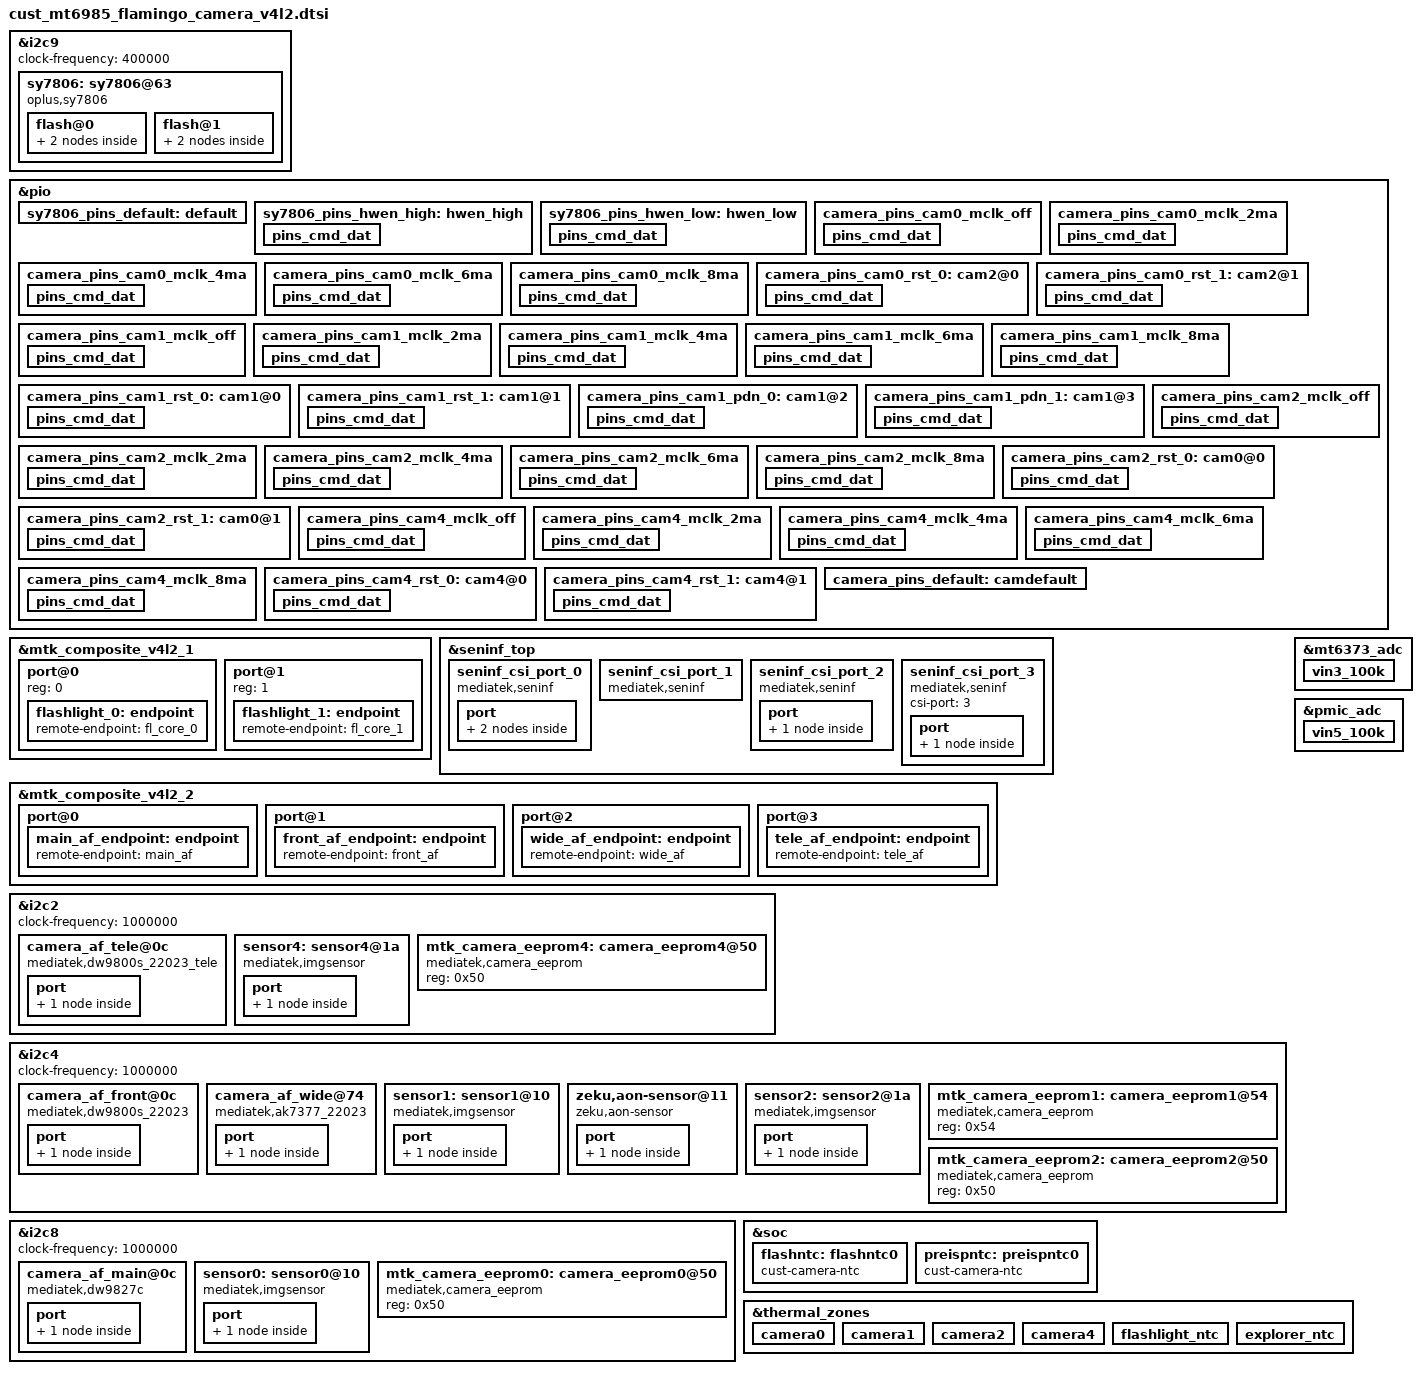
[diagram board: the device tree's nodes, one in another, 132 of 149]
// SPDX-License-Identifier: GPL-2.0
/* Copyright (c) 2020 MediaTek Inc. */

#include <dt-bindings/clock/mt6985-clk.h>
#include "mediatek/flamingo-regulator.dtsi"
&i2c9 {
	clock-frequency = <400000>;
	#address-cells = <1>;
	#size-cells = <0>;
	sy7806:sy7806@63 {
		compatible = "oplus,sy7806";
		#address-cells = <1>;
		#size-cells = <0>;
		reg = <0x63>;
		#cooling-cells = <2>;
		pinctrl-names = "default", "hwen_high", "hwen_low";
		pinctrl-0 = <&sy7806_pins_default>;
		pinctrl-1 = <&sy7806_pins_hwen_high>;
		pinctrl-2 = <&sy7806_pins_hwen_low>;
		status = "okay";
		flash@0{
			reg = <0>;
			type = <0>;
			ct = <0>;
			part = <0>;
			port {
				fl_core_0: endpoint {
					remote-endpoint = <&flashlight_0>;
				};
			};
		};
		flash@1{
			reg = <1>;
			type = <0>;
			ct = <1>;
			part = <0>;
			port {
				fl_core_1: endpoint {
					remote-endpoint = <&flashlight_1>;
				};
			};
		};
	};
};

&pio {
	sy7806_pins_default: default {
	};

	sy7806_pins_hwen_high: hwen_high {
		pins_cmd_dat {
			pinmux = <PINMUX_GPIO33__FUNC_GPIO33>;
			slew-rate = <1>;
			output-high;
		};
	};

	sy7806_pins_hwen_low: hwen_low {
		pins_cmd_dat {
			pinmux = <PINMUX_GPIO33__FUNC_GPIO33>;
			slew-rate = <1>;
			output-low;
		};
	};
};

&mtk_composite_v4l2_1 {
	#address-cells = <1>;
	#size-cells = <0>;
	port@0 {
		reg = <0>;
		flashlight_0: endpoint {
			remote-endpoint = <&fl_core_0>;
		};
	};
	port@1 {
		reg = <1>;
		flashlight_1: endpoint {
			remote-endpoint = <&fl_core_1>;
		};
	};
};

&seninf_top {
		seninf_csi_port_0: seninf_csi_port_0 {
			compatible = "mediatek,seninf";
			csi-port = "0";
			dphy_settle_delay_dt = <17>;
#if 0
			nvmem-cells = <&csi_efuse0>;
			nvmem-cell-names = "rg_csi";
#endif
			port {
				seninf_csi_port_0_in: endpoint@0 {
					remote-endpoint = <&sensor1_out>;
				};
				seninf_csi_port_0_in2: endpoint@1 {
					remote-endpoint = <&sensor2_out>;
				};
			};
		};

		seninf_csi_port_1: seninf_csi_port_1 {
			compatible = "mediatek,seninf";
			csi-port = "1";
			hs_trail_parameter = <0x20>;
#if 0
			nvmem-cells = <&csi_efuse1>;
			nvmem-cell-names = "rg_csi";
#endif
			//port {
			// 	seninf_csi_port_1_in: endpoint {
			// 		remote-endpoint = <&sensor4_out>;
			// 	};
			// };
		};

		seninf_csi_port_2: seninf_csi_port_2 {
			compatible = "mediatek,seninf";
			csi-port = "2";
			hs_trail_parameter = <0x20>;
#if 0
			nvmem-cells = <&csi_efuse2>;
			nvmem-cell-names = "rg_csi";
#endif
			port {
				seninf_csi_port_2_in: endpoint {
					remote-endpoint = <&sensor0_out>;
				};
			};
		};

		seninf_csi_port_3: seninf_csi_port_3 {
			compatible = "mediatek,seninf";
			csi-port = "3";
#if 0
			nvmem-cells = <&csi_efuse2>;
			nvmem-cell-names = "rg_csi";
#endif
			port {
				seninf_csi_port_3_in: endpoint {
					remote-endpoint = <&sensor4_out>;
				};
			};
		};
};

/* CAMERA GPIO standardization */
&pio {
	/* REAR0 IMX890: MCLK-GPIO208, RESET-GPIO202 */
	camera_pins_cam0_mclk_off: camera_pins_cam0_mclk_off {
		pins_cmd_dat {
			pinmux = <PINMUX_GPIO208__FUNC_GPIO208>;
			drive-strength = <1>;
		};
	};
	camera_pins_cam0_mclk_2ma: camera_pins_cam0_mclk_2ma {
		pins_cmd_dat {
			pinmux = <PINMUX_GPIO208__FUNC_CMMCLK3>;
			drive-strength = <0>;
		};
	};
	camera_pins_cam0_mclk_4ma: camera_pins_cam0_mclk_4ma {
		pins_cmd_dat {
			pinmux = <PINMUX_GPIO208__FUNC_CMMCLK3>;
			drive-strength = <1>;
		};
	};
	camera_pins_cam0_mclk_6ma: camera_pins_cam0_mclk_6ma {
		pins_cmd_dat {
			pinmux = <PINMUX_GPIO208__FUNC_CMMCLK3>;
			drive-strength = <2>;
		};
	};
	camera_pins_cam0_mclk_8ma: camera_pins_cam0_mclk_8ma {
		pins_cmd_dat {
			pinmux = <PINMUX_GPIO208__FUNC_CMMCLK3>;
			drive-strength = <3>;
		};
	};
	camera_pins_cam0_rst_0: cam2@0 {
		pins_cmd_dat {
			pinmux = <PINMUX_GPIO202__FUNC_GPIO202>;
			slew-rate = <1>;
			output-low;
		};
	};
	camera_pins_cam0_rst_1: cam2@1 {
		pins_cmd_dat {
			pinmux = <PINMUX_GPIO202__FUNC_GPIO202>;
			slew-rate = <1>;
			output-high;
		};
	};
/*	camera_pins_cam0_avdd1_0: cam2@2 {
		pins_cmd_dat {
			pinmux = <PINMUX_GPIO15__FUNC_GPIO15>;
			slew-rate = <1>;
			output-low;
		};
	};
	camera_pins_cam0_avdd1_1: cam2@3 {
		pins_cmd_dat {
			pinmux = <PINMUX_GPIO15__FUNC_GPIO15>;
			slew-rate = <1>;
			output-high;
		};
	};*/
	/* FRONT IMX709: MCLK-GPIO196, RESET-GPIO148 */
	camera_pins_cam1_mclk_off: camera_pins_cam1_mclk_off {
		pins_cmd_dat {
			pinmux = <PINMUX_GPIO196__FUNC_GPIO196>;
			drive-strength = <1>;
		};
	};
	camera_pins_cam1_mclk_2ma: camera_pins_cam1_mclk_2ma {
		pins_cmd_dat {
			pinmux = <PINMUX_GPIO196__FUNC_CMMCLK0>;
			drive-strength = <0>;
		};
	};
	camera_pins_cam1_mclk_4ma: camera_pins_cam1_mclk_4ma {
		pins_cmd_dat {
			pinmux = <PINMUX_GPIO196__FUNC_CMMCLK0>;
			drive-strength = <1>;
		};
	};
	camera_pins_cam1_mclk_6ma: camera_pins_cam1_mclk_6ma {
		pins_cmd_dat {
			pinmux = <PINMUX_GPIO196__FUNC_CMMCLK0>;
			drive-strength = <2>;
		};
	};
	camera_pins_cam1_mclk_8ma: camera_pins_cam1_mclk_8ma {
		pins_cmd_dat {
			pinmux = <PINMUX_GPIO196__FUNC_CMMCLK0>;
			drive-strength = <3>;
		};
	};
	camera_pins_cam1_rst_0: cam1@0 {
		pins_cmd_dat {
			pinmux = <PINMUX_GPIO148__FUNC_GPIO148>;
			slew-rate = <1>;
			output-low;
		};
	};
	camera_pins_cam1_rst_1: cam1@1 {
		pins_cmd_dat {
			pinmux = <PINMUX_GPIO148__FUNC_GPIO148>;
			slew-rate = <1>;
			output-high;
		};
	};
	camera_pins_cam1_pdn_0: cam1@2 {
		pins_cmd_dat {
			pinmux = <PINMUX_GPIO149__FUNC_GPIO149>;
			slew-rate = <1>;
			output-low;
		};
	};
	camera_pins_cam1_pdn_1: cam1@3 {
		pins_cmd_dat {
			pinmux = <PINMUX_GPIO149__FUNC_GPIO149>;
			slew-rate = <1>;
			output-high;
		};
	};
	/* REAR1 IMX581: MCLK-GPIO198, RESET-GPIO201 */
	camera_pins_cam2_mclk_off: camera_pins_cam2_mclk_off {
		pins_cmd_dat {
			pinmux = <PINMUX_GPIO198__FUNC_GPIO198>;
			drive-strength = <1>;
		};
	};
	camera_pins_cam2_mclk_2ma: camera_pins_cam2_mclk_2ma {
		pins_cmd_dat {
			pinmux = <PINMUX_GPIO198__FUNC_CMMCLK2>;
			drive-strength = <0>;
		};
	};
	camera_pins_cam2_mclk_4ma: camera_pins_cam2_mclk_4ma {
		pins_cmd_dat {
			pinmux = <PINMUX_GPIO198__FUNC_CMMCLK2>;
			drive-strength = <1>;
		};
	};
	camera_pins_cam2_mclk_6ma: camera_pins_cam2_mclk_6ma {
		pins_cmd_dat {
			pinmux = <PINMUX_GPIO198__FUNC_CMMCLK2>;
			drive-strength = <2>;
		};
	};
	camera_pins_cam2_mclk_8ma: camera_pins_cam2_mclk_8ma {
		pins_cmd_dat {
			pinmux = <PINMUX_GPIO198__FUNC_CMMCLK2>;
			drive-strength = <3>;
		};
	};
	camera_pins_cam2_rst_0: cam0@0 {
		pins_cmd_dat {
			pinmux = <PINMUX_GPIO201__FUNC_GPIO201>;
			slew-rate = <1>;
			output-low;
		};
	};
	camera_pins_cam2_rst_1: cam0@1 {
		pins_cmd_dat {
			pinmux = <PINMUX_GPIO201__FUNC_GPIO201>;
			slew-rate = <1>;
			output-high;
		};
	};
	/* REAR2 IMX709TELE: MCLK-GPIO197, RESET-GPIO200 */
	camera_pins_cam4_mclk_off: camera_pins_cam4_mclk_off {
		pins_cmd_dat {
			pinmux = <PINMUX_GPIO197__FUNC_GPIO197>;
			drive-strength = <1>;
		};
	};
	camera_pins_cam4_mclk_2ma: camera_pins_cam4_mclk_2ma {
		pins_cmd_dat {
			pinmux = <PINMUX_GPIO197__FUNC_CMMCLK1>;
			drive-strength = <0>;
		};
	};
	camera_pins_cam4_mclk_4ma: camera_pins_cam4_mclk_4ma {
		pins_cmd_dat {
			pinmux = <PINMUX_GPIO197__FUNC_CMMCLK1>;
			drive-strength = <1>;
		};
	};
	camera_pins_cam4_mclk_6ma: camera_pins_cam4_mclk_6ma {
		pins_cmd_dat {
			pinmux = <PINMUX_GPIO197__FUNC_CMMCLK1>;
			drive-strength = <2>;
		};
	};
	camera_pins_cam4_mclk_8ma: camera_pins_cam4_mclk_8ma {
		pins_cmd_dat {
			pinmux = <PINMUX_GPIO197__FUNC_CMMCLK1>;
			drive-strength = <3>;
		};
	};
	camera_pins_cam4_rst_0: cam4@0 {
		pins_cmd_dat {
			pinmux = <PINMUX_GPIO200__FUNC_GPIO200>;
			slew-rate = <1>;
			output-low;
		};
	};
	camera_pins_cam4_rst_1: cam4@1 {
		pins_cmd_dat {
			pinmux = <PINMUX_GPIO200__FUNC_GPIO200>;
			slew-rate = <1>;
			output-high;
		};
	};
	camera_pins_default: camdefault {
	};
};
/* CAMERA GPIO end */


&mtk_composite_v4l2_2 {
	port@0 {
		main_af_endpoint: endpoint {
			remote-endpoint = <&main_af>;
		};
	};
	port@1 {
		front_af_endpoint: endpoint {
			remote-endpoint = <&front_af>;
		};
	};
	port@2 {
		wide_af_endpoint: endpoint {
			remote-endpoint = <&wide_af>;
		};
	};
	port@3 {
		tele_af_endpoint: endpoint {
			remote-endpoint = <&tele_af>;
		};
	};
};

&i2c2 {
	status = "okay";
	clock-frequency = <1000000>;
	#address-cells = <1>;
	#size-cells = <0>;

	camera_af_tele@0c {
		compatible = "mediatek,dw9800s_22023_tele";
		reg = <0x0c>;
		vin-supply = <&wl2868c_ldo7a>;
		port {
			tele_af: endpoint {
				remote-endpoint = <&tele_af_endpoint>;
			};
		};
	};

	sensor4: sensor4@1a {
		compatible = "mediatek,imgsensor";
		sensor-names = "imx709tele_mipi_raw_22023";
		reg = <0x1a>;
		#thermal-sensor-cells = <0>;

		pinctrl-names = "mclk_off",
				"mclk_2mA",
				"mclk_4mA",
				"mclk_6mA",
				"mclk_8mA",
				"rst_low",
				"rst_high";
		pinctrl-0 = <&camera_pins_cam4_mclk_off>;
		pinctrl-1 = <&camera_pins_cam4_mclk_2ma>;
		pinctrl-2 = <&camera_pins_cam4_mclk_4ma>;
		pinctrl-3 = <&camera_pins_cam4_mclk_6ma>;
		pinctrl-4 = <&camera_pins_cam4_mclk_8ma>;
		pinctrl-5 = <&camera_pins_cam4_rst_0>;
		pinctrl-6 = <&camera_pins_cam4_rst_1>;

		avdd-supply = <&wl2868c_ldo6a>;
		dvdd-supply = <&wl2868c_ldo2b>;
		dovdd-supply = <&wl2868c_ldo5b>;
		afvdd-supply = <&wl2868c_ldo7a>;

		clocks = <&topckgen_clk CLK_TOP_UNIVPLL2_192M_D32>,
			<&topckgen_clk CLK_TOP_UNIVPLL2_192M_D16>,
			<&topckgen_clk CLK_TOP_F26M_CK_D2>,
			<&topckgen_clk CLK_TOP_UNIVPLL2_192M_D10>,
			<&topckgen_clk CLK_TOP_UNIVPLL2_192M_D8>,
			<&topckgen_clk CLK_TOP_TCK_26M_MX9>,
			<&topckgen_clk CLK_TOP_UNIVPLL2_D6_D8>,
			<&topckgen_clk CLK_TOP_CAMTG2_SEL>;
		clock-names = "6", "12", "13", "19.2", "24", "26", "52", "mclk";

		status = "okay";

		port {
			sensor4_out: endpoint {
				remote-endpoint = <&seninf_csi_port_3_in>;
			};
		};
	};

	mtk_camera_eeprom4:camera_eeprom4@50 {
		compatible = "mediatek,camera_eeprom";
		reg = <0x50>;
		status = "okay";
	};
};

&i2c4 {
	status = "okay";
	clock-frequency = <1000000>;
	#address-cells = <1>;
	#size-cells = <0>;

	camera_af_front@0c {
		compatible = "mediatek,dw9800s_22023";
		reg = <0x0c>;
		vin-supply = <&wl2868c_ldo7a>;
		port {
			front_af: endpoint {
				remote-endpoint = <&front_af_endpoint>;
			};
		};
	};

	/* WIDE Camera imx581*/
	camera_af_wide@74 {
		compatible = "mediatek,ak7377_22023";
		reg = <0x74>;
		vin-supply = <&wl2868c_ldo7b>;
		port {
			wide_af: endpoint {
				remote-endpoint = <&wide_af_endpoint>;
			};
		};
	};

	sensor1: sensor1@10 {
		compatible = "mediatek,imgsensor";
		sensor-names = "imx709_mipi_raw_22023";
		reg = <0x10>;
		#thermal-sensor-cells = <0>;

		pinctrl-names = "mclk_off",
				"mclk_2mA",
				"mclk_4mA",
				"mclk_6mA",
				"mclk_8mA",
				"rst_low",
				"rst_high",
				"pdn_low",
				"pdn_high";
		pinctrl-0 = <&camera_pins_cam1_mclk_off>;
		pinctrl-1 = <&camera_pins_cam1_mclk_2ma>;
		pinctrl-2 = <&camera_pins_cam1_mclk_4ma>;
		pinctrl-3 = <&camera_pins_cam1_mclk_6ma>;
		pinctrl-4 = <&camera_pins_cam1_mclk_8ma>;
		pinctrl-5 = <&camera_pins_cam1_rst_0>;
		pinctrl-6 = <&camera_pins_cam1_rst_1>;
		pinctrl-7 = <&camera_pins_cam1_pdn_0>;
		pinctrl-8 = <&camera_pins_cam1_pdn_1>;

		avdd-supply = <&wl2868c_ldo5a>;
		dvdd-supply = <&wl2868c_ldo2a>;
		dovdd-supply = <&wl2868c_ldo5b>;
		afvdd-supply = <&wl2868c_ldo7a>;

		clocks = <&topckgen_clk CLK_TOP_UNIVPLL_192M_D32>,
			<&topckgen_clk CLK_TOP_UNIVPLL_192M_D16>,
			<&topckgen_clk CLK_TOP_F26M_CK_D2>,
			<&topckgen_clk CLK_TOP_UNIVPLL_192M_D10>,
			<&topckgen_clk CLK_TOP_UNIVPLL_192M_D8>,
			<&topckgen_clk CLK_TOP_UNIVPLL_D6_D16>,
			<&topckgen_clk CLK_TOP_UNIVPLL_D6_D8>,
			<&vlp_cksys_clk CLK_VLP_CK_CAMTG_VLP_SEL>;
		clock-names = "6", "12", "13", "19.2", "24", "26", "52", "mclk";

		status = "okay";
		/*If this project use explorer AON driver, set this flag as ture.*/
		support_explorer_aon = "true";
		aon-irq-gpio = <&pio 188 0x0>;

		port {
			sensor1_out: endpoint {
				remote-endpoint = <&seninf_csi_port_0_in>;
			};
		};
	};

	zeku,aon-sensor@11 {
		compatible = "zeku,aon-sensor";
		reg = <0x11>;

		pinctrl-names = "mclk_off",
				"mclk_2mA",
				"mclk_4mA",
				"mclk_6mA",
				"mclk_8mA",
				"rst_low",
				"rst_high",
				"pdn_low",
				"pdn_high";
		pinctrl-0 = <&camera_pins_cam1_mclk_off>;
		pinctrl-1 = <&camera_pins_cam1_mclk_2ma>;
		pinctrl-2 = <&camera_pins_cam1_mclk_4ma>;
		pinctrl-3 = <&camera_pins_cam1_mclk_6ma>;
		pinctrl-4 = <&camera_pins_cam1_mclk_8ma>;
		pinctrl-5 = <&camera_pins_cam1_rst_0>;
		pinctrl-6 = <&camera_pins_cam1_rst_1>;
		pinctrl-7 = <&camera_pins_cam1_pdn_0>;
		pinctrl-8 = <&camera_pins_cam1_pdn_1>;

		avdd-supply = <&wl2868c_ldo5a>;
		dvdd-supply = <&wl2868c_ldo2a>;
		dovdd-supply = <&wl2868c_ldo5b>;
		afvdd-supply = <&wl2868c_ldo7a>;
		regulator-names = "avdd", "dvdd","dovdd","afvdd";

		clocks = <&topckgen_clk CLK_TOP_UNIVPLL_192M_D32>,
			<&topckgen_clk CLK_TOP_UNIVPLL_192M_D16>,
			<&topckgen_clk CLK_TOP_F26M_CK_D2>,
			<&topckgen_clk CLK_TOP_UNIVPLL_192M_D10>,
			<&topckgen_clk CLK_TOP_UNIVPLL_192M_D8>,
			<&topckgen_clk CLK_TOP_UNIVPLL_D6_D16>,
			<&topckgen_clk CLK_TOP_UNIVPLL_D6_D8>,
			<&vlp_cksys_clk CLK_VLP_CK_CAMTG_VLP_SEL>;
		clock-names = "6", "12", "13", "19.2", "24", "26", "52", "mclk";

		port {
			aon_sensor1_out: endpoint {
				remote-endpoint = <&seninf_csi_port_0_in>;
			};
		};
	};

	sensor2: sensor2@1a {
		compatible = "mediatek,imgsensor";
		sensor-names = "imx581_mipi_raw_22023";
		reg = <0x1a>;
		#thermal-sensor-cells = <0>;

		pinctrl-names = "mclk_off",
				"mclk_2mA",
				"mclk_4mA",
				"mclk_6mA",
				"mclk_8mA",
				"rst_low",
				"rst_high";
		pinctrl-0 = <&camera_pins_cam2_mclk_off>;
		pinctrl-1 = <&camera_pins_cam2_mclk_2ma>;
		pinctrl-2 = <&camera_pins_cam2_mclk_4ma>;
		pinctrl-3 = <&camera_pins_cam2_mclk_6ma>;
		pinctrl-4 = <&camera_pins_cam2_mclk_8ma>;
		pinctrl-5 = <&camera_pins_cam2_rst_0>;
		pinctrl-6 = <&camera_pins_cam2_rst_1>;

		avdd-supply = <&wl2868c_ldo6b>;
		avdd1-supply = <&wl2868c_ldo3b>;
		dvdd-supply = <&wl2868c_ldo1b>;
		dovdd-supply = <&wl2868c_ldo5b>;
		afvdd-supply = <&wl2868c_ldo7b>;

		clocks = <&topckgen_clk CLK_TOP_UNIVPLL2_192M_D32>,
			<&topckgen_clk CLK_TOP_UNIVPLL2_192M_D16>,
			<&topckgen_clk CLK_TOP_F26M_CK_D2>,
			<&topckgen_clk CLK_TOP_UNIVPLL2_192M_D10>,
			<&topckgen_clk CLK_TOP_UNIVPLL2_192M_D8>,
			<&topckgen_clk CLK_TOP_TCK_26M_MX9>,
			<&topckgen_clk CLK_TOP_UNIVPLL2_D6_D8>,
			<&topckgen_clk CLK_TOP_CAMTG3_SEL>;
		clock-names = "6", "12", "13", "19.2", "24", "26", "52", "mclk";

		status = "okay";

		port {
			sensor2_out: endpoint {
				remote-endpoint = <&seninf_csi_port_0_in2>;
			};
		};
	};

	mtk_camera_eeprom1:camera_eeprom1@54 {
		compatible = "mediatek,camera_eeprom";
		reg = <0x54>;
		status = "okay";
	};

	mtk_camera_eeprom2:camera_eeprom2@50 {
		compatible = "mediatek,camera_eeprom";
		reg = <0x50>;
		status = "okay";
	};
};

&i2c8 {
	status = "okay";
	clock-frequency = <1000000>;
	#address-cells = <1>;
	#size-cells = <0>;

	camera_af_main@0c {
		compatible = "mediatek,dw9827c";
		reg = <0x0c>;
		vin-supply = <&wl2868c_ldo4a>;
		port {
			main_af: endpoint {
				remote-endpoint = <&main_af_endpoint>;
			};
		};
	};

	sensor0: sensor0@10 {
		compatible = "mediatek,imgsensor";
		sensor-names = "imx890_mipi_raw_22023";
		reg = <0x10>;
		#thermal-sensor-cells = <0>;

		pinctrl-names = "mclk_off",
				"mclk_2mA",
				"mclk_4mA",
				"mclk_6mA",
				"mclk_8mA",
				"rst_low",
				"rst_high";
		pinctrl-0 = <&camera_pins_cam0_mclk_off>;
		pinctrl-1 = <&camera_pins_cam0_mclk_2ma>;
		pinctrl-2 = <&camera_pins_cam0_mclk_4ma>;
		pinctrl-3 = <&camera_pins_cam0_mclk_6ma>;
		pinctrl-4 = <&camera_pins_cam0_mclk_8ma>;
		pinctrl-5 = <&camera_pins_cam0_rst_0>;
		pinctrl-6 = <&camera_pins_cam0_rst_1>;

		avdd1-supply = <&wl2868c_ldo4b>;
		avdd-supply = <&wl2868c_ldo3a>;
		dvdd-supply = <&wl2868c_ldo1a>;
		dovdd-supply = <&wl2868c_ldo5b>;
		afvdd-supply = <&wl2868c_ldo4a>;

		clocks = <&topckgen_clk CLK_TOP_UNIVPLL2_192M_D32>,
			<&topckgen_clk CLK_TOP_UNIVPLL2_192M_D16>,
			<&topckgen_clk CLK_TOP_F26M_CK_D2>,
			<&topckgen_clk CLK_TOP_UNIVPLL2_192M_D10>,
			<&topckgen_clk CLK_TOP_UNIVPLL2_192M_D8>,
			<&topckgen_clk CLK_TOP_TCK_26M_MX9>,
			<&topckgen_clk CLK_TOP_UNIVPLL2_D6_D8>,
			<&topckgen_clk CLK_TOP_CAMTG4_SEL>;
		clock-names = "6", "12", "13", "19.2", "24", "26", "52", "mclk";

		status = "okay";

		port {
			sensor0_out: endpoint {
				remote-endpoint = <&seninf_csi_port_2_in>;
			};
		};
	};

	mtk_camera_eeprom0:camera_eeprom0@50 {
		compatible = "mediatek,camera_eeprom";
		reg = <0x50>;
		status = "okay";
	};
};

&mt6373_adc {
	vin3_100k {
		channel = <AUXADC_VIN3>;
		pures = <ADC_PURES_100K>;
	};
};
&pmic_adc {
	vin5_100k {
		channel = <AUXADC_VIN5>;
		pures = <ADC_PURES_100K>;
	};
};
&soc {
	flashntc: flashntc0 {
		compatible = "cust-camera-ntc";
		#thermal-sensor-cells = <0>;
		io-channels = <&mt6373_adc (ADC_PURES_100K_MASK | AUXADC_VIN3)>;
		io-channel-names = "sensor-channel";
		temperature-lookup-table =
			<(-40000) 1760>,
			<(-39000) 1757>,
			<(-38000) 1754>,
			<(-37000) 1751>,
			<(-36000) 1747>,
			<(-35000) 1744>,
			<(-34000) 1740>,
			<(-33000) 1736>,
			<(-32000) 1731>,
			<(-31000) 1727>,
			<(-30000) 1722>,
			<(-29000) 1716>,
			<(-28000) 1711>,
			<(-27000) 1705>,
			<(-26000) 1699>,
			<(-25000) 1693>,
			<(-24000) 1686>,
			<(-23000) 1679>,
			<(-22000) 1672>,
			<(-21000) 1664>,
			<(-20000) 1656>,
			<(-19000) 1648>,
			<(-18000) 1639>,
			<(-17000) 1630>,
			<(-16000) 1620>,
			<(-15000) 1610>,
			<(-14000) 1599>,
			<(-13000) 1588>,
			<(-12000) 1577>,
			<(-11000) 1565>,
			<(-10000) 1553>,
			<(-9000) 1541>,
			<(-8000) 1528>,
			<(-7000) 1514>,
			<(-6000) 1500>,
			<(-5000) 1486>,
			<(-4000) 1471>,
			<(-3000) 1455>,
			<(-2000) 1439>,
			<(-1000) 1424>,
			<0 1407>,
			<1000 1390>,
			<2000 1373>,
			<3000 1355>,
			<4000 1337>,
			<5000 1318>,
			<6000 1299>,
			<7000 1280>,
			<8000 1261>,
			<9000 1241>,
			<10000 1221>,
			<11000 1200>,
			<12000 1180>,
			<13000 1159>,
			<14000 1138>,
			<15000 1117>,
			<16000 1096>,
			<17000 1075>,
			<18000 1054>,
			<19000 1032>,
			<20000 1011>,
			<21000 989>,
			<22000 968>,
			<23000 947>,
			<24000 926>,
			<25000 904>,
			<26000 883>,
			<27000 863>,
			<28000 842>,
			<29000 822>,
			<30000 801>,
			<31000 781>,
			<32000 761>,
			<33000 742>,
			<34000 723>,
			<35000 704>,
			<36000 685>,
			<37000 666>,
			<38000 648>,
			<39000 631>,
			<40000 613>,
			<41000 596>,
			<42000 580>,
			<43000 563>,
			<44000 547>,
			<45000 532>,
			<46000 516>,
			<47000 501>,
			<48000 487>,
			<49000 473>,
			<50000 459>,
			<51000 445>,
			<52000 432>,
			<53000 419>,
			<54000 406>,
			<55000 395>,
			<56000 383>,
			<57000 372>,
			<58000 360>,
			<59000 350>,
			<60000 339>,
			<61000 329>,
			<62000 319>,
			<63000 310>,
			<64000 300>,
			<65000 291>,
			<66000 283>,
			<67000 274>,
			<68000 266>,
			<69000 258>,
			<70000 251>,
			<71000 243>,
			<72000 236>,
			<73000 229>,
			<74000 222>,
			<75000 216>,
			<76000 210>,
			<77000 204>,
			<78000 198>,
			<79000 192>,
			<80000 187>,
			<81000 181>,
			<82000 176>,
			<83000 171>,
			<84000 166>,
			<85000 162>,
			<86000 157>,
			<87000 153>,
			<88000 149>,
			<89000 145>,
			<90000 141>,
			<91000 137>,
			<92000 133>,
			<93000 130>,
			<94000 126>,
			<95000 123>,
			<96000 120>,
			<97000 117>,
			<98000 114>,
			<99000 111>,
			<100000 108>,
			<101000 105>,
			<102000 103>,
			<103000 100>,
			<104000 98>,
			<105000 95>,
			<106000 93>,
			<107000 91>,
			<108000 89>,
			<109000 87>,
			<110000 85>,
			<111000 83>,
			<112000 81>,
			<113000 79>,
			<114000 77>,
			<115000 76>,
			<116000 74>,
			<117000 72>,
			<118000 71>,
			<119000 69>,
			<120000 68>,
			<121000 66>,
			<122000 65>,
			<123000 64>,
			<124000 62>,
			<125000 61>;
	};
	preispntc: preispntc0 {
		compatible = "cust-camera-ntc";
		#thermal-sensor-cells = <0>;
		io-channels = <&pmic_adc (ADC_PURES_100K_MASK | AUXADC_VIN5)>;
		io-channel-names = "sensor-channel";
		temperature-lookup-table =
			<(-40000) 1760>,
			<(-39000) 1757>,
			<(-38000) 1754>,
			<(-37000) 1751>,
			<(-36000) 1747>,
			<(-35000) 1744>,
			<(-34000) 1740>,
			<(-33000) 1736>,
			<(-32000) 1731>,
			<(-31000) 1727>,
			<(-30000) 1722>,
			<(-29000) 1716>,
			<(-28000) 1711>,
			<(-27000) 1705>,
			<(-26000) 1699>,
			<(-25000) 1693>,
			<(-24000) 1686>,
			<(-23000) 1679>,
			<(-22000) 1672>,
			<(-21000) 1664>,
			<(-20000) 1656>,
			<(-19000) 1648>,
			<(-18000) 1639>,
			<(-17000) 1630>,
			<(-16000) 1620>,
			<(-15000) 1610>,
			<(-14000) 1599>,
			<(-13000) 1588>,
			<(-12000) 1577>,
			<(-11000) 1565>,
			<(-10000) 1553>,
			<(-9000) 1540>,
			<(-8000) 1527>,
			<(-7000) 1514>,
			<(-6000) 1500>,
			<(-5000) 1485>,
			<(-4000) 1470>,
			<(-3000) 1455>,
			<(-2000) 1439>,
			<(-1000) 1423>,
			<0 1406>,
			<1000 1389>,
			<2000 1372>,
			<3000 1354>,
			<4000 1335>,
			<5000 1317>,
			<6000 1298>,
			<7000 1279>,
			<8000 1259>,
			<9000 1239>,
			<10000 1219>,
			<11000 1198>,
			<12000 1178>,
			<13000 1157>,
			<14000 1136>,
			<15000 1115>,
			<16000 1093>,
			<17000 1072>,
			<18000 1050>,
			<19000 1029>,
			<20000 1007>,
			<21000 986>,
			<22000 964>,
			<23000 943>,
			<24000 921>,
			<25000 900>,
			<26000 879>,
			<27000 858>,
			<28000 837>,
			<29000 816>,
			<30000 796>,
			<31000 775>,
			<32000 755>,
			<33000 736>,
			<34000 716>,
			<35000 697>,
			<36000 678>,
			<37000 659>,
			<38000 641>,
			<39000 623>,
			<40000 605>,
			<41000 588>,
			<42000 571>,
			<43000 555>,
			<44000 538>,
			<45000 523>,
			<46000 507>,
			<47000 492>,
			<48000 477>,
			<49000 463>,
			<50000 449>,
			<51000 435>,
			<52000 422>,
			<53000 409>,
			<54000 396>,
			<55000 384>,
			<56000 372>,
			<57000 360>,
			<58000 349>,
			<59000 338>,
			<60000 327>,
			<61000 317>,
			<62000 307>,
			<63000 297>,
			<64000 288>,
			<65000 279>,
			<66000 270>,
			<67000 261>,
			<68000 253>,
			<69000 245>,
			<70000 237>,
			<71000 230>,
			<72000 222>,
			<73000 215>,
			<74000 209>,
			<75000 202>,
			<76000 196>,
			<77000 189>,
			<78000 183>,
			<79000 178>,
			<80000 172>,
			<81000 167>,
			<82000 161>,
			<83000 156>,
			<84000 151>,
			<85000 147>,
			<86000 142>,
			<87000 138>,
			<88000 133>,
			<89000 129>,
			<90000 125>,
			<91000 121>,
			<92000 118>,
			<93000 114>,
			<94000 111>,
			<95000 107>,
			<96000 104>,
			<97000 101>,
			<98000 98>,
			<99000 95>,
			<100000 92>,
			<101000 89>,
			<102000 87>,
			<103000 84>,
			<104000 81>,
			<105000 79>,
			<106000 77>,
			<107000 74>,
			<108000 72>,
			<109000 70>,
			<110000 68>,
			<111000 66>,
			<112000 64>,
			<113000 62>,
			<114000 61>,
			<115000 59>,
			<116000 57>,
			<117000 56>,
			<118000 54>,
			<119000 52>,
			<120000 51>,
			<121000 50>,
			<122000 48>,
			<123000 47>,
			<124000 46>,
			<125000 44>;
	};
};

&thermal_zones {
	camera0: camera0 {
		polling-delay = <0>; /* milliseconds */
		polling-delay-passive = <0>; /* milliseconds */
		thermal-sensors = <&sensor0>;
	};
	camera1: camera1 {
		polling-delay = <0>; /* milliseconds */
		polling-delay-passive = <0>; /* milliseconds */
		thermal-sensors = <&sensor1>;
	};
	camera2: camera2 {
		polling-delay = <0>; /* milliseconds */
		polling-delay-passive = <0>; /* milliseconds */
		thermal-sensors = <&sensor2>;
	};
	camera4: camera4 {
		polling-delay = <0>; /* milliseconds */
		polling-delay-passive = <0>; /* milliseconds */
		thermal-sensors = <&sensor4>;
	};
	flashlight_ntc: flashlight_ntc {
		polling-delay = <0>; /* milliseconds */
		polling-delay-passive = <0>; /* milliseconds */
		thermal-sensors = <&flashntc>;
	};
	explorer_ntc: explorer_ntc {
		polling-delay = <0>; /* milliseconds */
		polling-delay-passive = <0>; /* milliseconds */
		thermal-sensors = <&preispntc>;
	};
};

